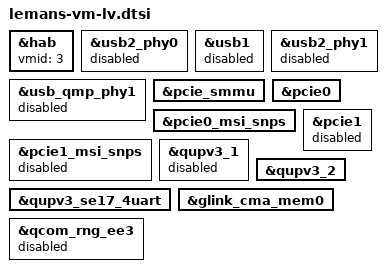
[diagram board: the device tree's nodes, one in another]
// SPDX-License-Identifier: BSD-3-Clause
/*
 * Copyright (c) Qualcomm Technologies, Inc. and/or its subsidiaries.
 */

&hab {
	vmid = <3>;
};

&usb2_phy0 {
	status = "disabled";
};

&usb1 {
	/delete-property/ qcom,host-poweroff-in-pm-suspend;
	/delete-property/ qcom,default-mode-host;
	status = "disabled";
};

&usb2_phy1 {
	status = "disabled";
};

&usb_qmp_phy1 {
	status = "disabled";
};

&pcie_smmu {
	status = "ok";
};

&pcie0 {
	status = "ok";
};

&pcie0_msi_snps {
	status = "ok";
};

&pcie1 {
	status = "disabled";
};

&pcie1_msi_snps {
	status = "disabled";
};

&qupv3_1 {
	status = "disabled";
};

&qupv3_2 {
	status = "ok";
};

&qupv3_se17_4uart {
	status = "ok";
};

&glink_cma_mem0 {
	status = "okay";
};

&qcom_rng_ee3 {
	status = "disabled";
};
